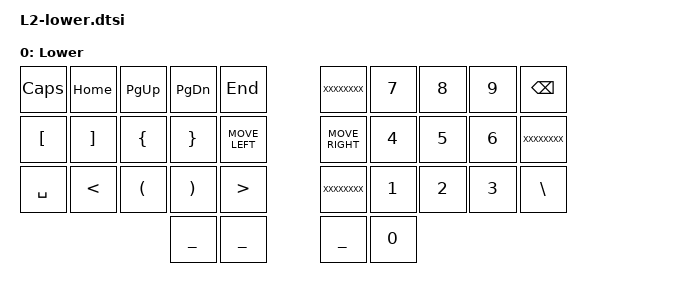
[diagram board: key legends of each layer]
/**
 *
 */

/ {
  keymap {
    compatible = "zmk,keymap";

	lower_layer {
		label = "Lower";
   		bindings = <
//	╭───────────────┬───────────────┬───────────────┬───────────────┬───────────────╮   ╭───────────────┬───────────────┬───────────────┬───────────────┬───────────────╮
	&kp CAPS		&kp HOME    	&kp PG_UP		&kp PG_DN		&kp END				XXXXXXXX		&kp N7			&kp N8       	&kp N9        	&kp BSPC
//	├───────────────┼───────────────┼───────────────┼───────────────┼───────────────┤   ├───────────────├───────────────┼───────────────┼───────────────┼───────────────┤
	&kp LBKT		&kp RBKT    	&kp LBRC 		&kp RBRC		MOVE_LEFT			MOVE_RIGHT		&kp N4			&kp N5       	&kp N6		    XXXXXXXX
//	├───────────────┼───────────────┼───────────────┼───────────────┼───────────────┤   ├───────────────├───────────────┼───────────────┼───────────────┼───────────────┤
	&kp SPACE		&kp LT    	    &kp LPAR		&kp RPAR		&kp GT 			XXXXXXXX		&kp N1			&kp N2       	&kp N3			&kp BSLH
//	╰───────────────┴───────────────┼───────────────┼───────────────┼───────────────┤   ├───────────────├───────────────┼───────────────┼───────────────┴───────────────╯
			       									________		________			________		&kp N0
//                                                  ╰───────────────┴───────────────╯   ╰───────────────┴───────────────╯
			>;
		};
	};
};
